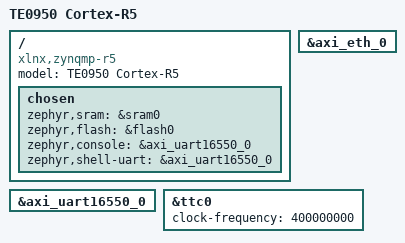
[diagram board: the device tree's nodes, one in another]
/*
 * Copyright (c) 2022 Linaro.
 *
 * SPDX-License-Identifier: Apache-2.0
 *
 */

/dts-v1/;
#include <arm/xilinx/versal_rpu.dtsi>

/ {
	model = "TE0950 Cortex-R5";
	compatible = "xlnx,zynqmp-r5";

	chosen {
		zephyr,sram = &sram0;
		zephyr,flash = &flash0;
		zephyr,console = &axi_uart16550_0;
		zephyr,shell-uart = &axi_uart16550_0;
	};
};

&axi_uart16550_0 {
	status = "okay";
};

&axi_eth_0 {
	status = "okay";
};


&ttc0 {
	status = "okay";
	clock-frequency = <400000000>;
};

